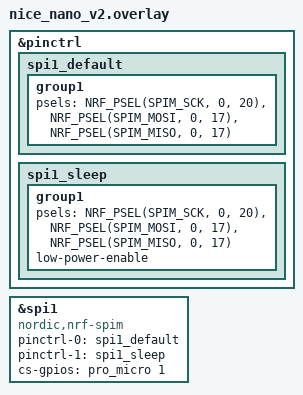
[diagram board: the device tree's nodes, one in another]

&pinctrl {
    spi1_default: spi1_default {
        group1 {
            psels = <NRF_PSEL(SPIM_SCK, 0, 20)>,
                <NRF_PSEL(SPIM_MOSI, 0, 17)>,
                <NRF_PSEL(SPIM_MISO, 0, 17)>;
        };
    };
    spi1_sleep: spi1_sleep {
        group1 {
            psels = <NRF_PSEL(SPIM_SCK, 0, 20)>,
                <NRF_PSEL(SPIM_MOSI, 0, 17)>,
                <NRF_PSEL(SPIM_MISO, 0, 17)>;
            low-power-enable;
        };
    };
};

nice_view_spi: &spi1 {
    compatible = "nordic,nrf-spim";
    pinctrl-0 = <&spi1_default>;
    pinctrl-1 = <&spi1_sleep>;
    pinctrl-names = "default", "sleep";
    cs-gpios = <&pro_micro 1 GPIO_ACTIVE_HIGH>;
};

